# STM32U3C5 register map
File version: 1.0
CPU: CM33 r0p1, little endian, MPU, FPU, 4 interrupt priority bits
Registers are 32-bit, read-write, reset 0x0 unless marked. A register's access mark holds for its fields unless they carry their own. Offsets are from the block's base; [hi:lo] are bit positions; {n}, {i} and the like mark numbered series.

## SPI1 — SPI address block description
Base 0x40013000
Same registers: SPI3 0x40002000, SPI4 0x40002400, SPI2 0x40003800, SEC_SPI3 0x50002000, SEC_SPI4 0x50002400, SEC_SPI2 0x50003800, SEC_SPI1 0x50013000
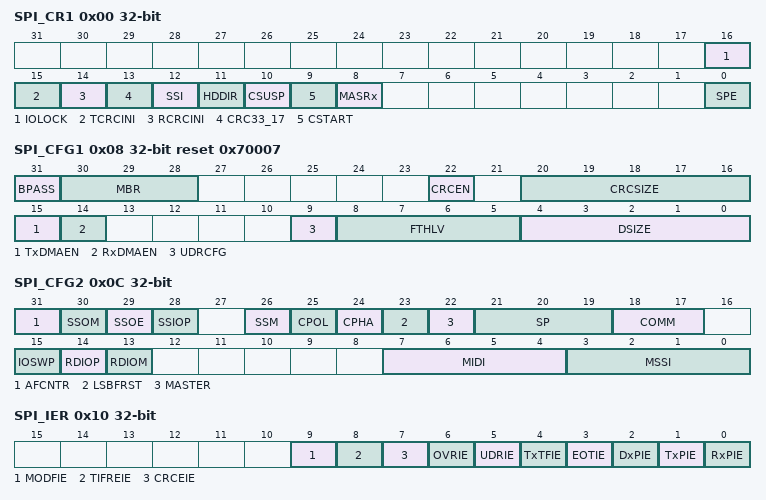
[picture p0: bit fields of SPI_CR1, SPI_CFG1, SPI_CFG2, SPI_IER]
0x00 SPI_CR1 — SPI control register 1
  [16] IOLOCK — locking the AF configuration of associated I/Os
    0=AF configuration is not locked; 1=AF configuration is locked
  [15] TCRCINI — CRC calculation initialization pattern control for transmitter
    0=all zero pattern is applied; 1=all ones pattern is applied
  [14] RCRCINI — CRC calculation initialization pattern control for receiver
    0=All zero pattern is applied; 1=All ones pattern is applied
  [13] CRC33_17 — Full size (33-bit or 17-bit) CRC polynomial configuration
    0=Full size (33-bit or 17-bit) CRC polynomial is not used; 1=Full size (33-bit or 17-bit) CRC polynomial is used
  [12] SSI — internal SS signal input level
  [11] HDDIR — Rx/Tx direction at half-duplex mode
    0=SPI is receiver; 1=SPI is transmitter
  [10] CSUSP wo — master suspend request
  [9] CSTART — master transfer start
    0=master transfer is at idle; 1=master transfer is ongoing or temporary suspended by automatic suspend
  [8] MASRx — master automatic suspension in Receive mode
    0=SPI flow/clock generation is continuous, regardless of overrun condition; 1=SPI flow is suspended temporary on RxFIFO full condition, before reaching overrun condition
  [0] SPE — serial peripheral enable
    0=Serial peripheral disabled; 1=Serial peripheral enabled
0x04 SPI_CR2 — SPI control register 2
  [15:0] TSIZE — number of data at current transfer
0x08 SPI_CFG1 reset 0x70007 — SPI configuration register 1
  [31] BPASS — bypass of the prescaler at master baud rate clock generator
    0=bypass is disabled; 1=bypass is enabled
  [30:28] MBR — master baud rate prescaler setting
    0=SPI master clock/2; 1=SPI master clock/4; 2=SPI master clock/8; 3=SPI master clock/16; 4=SPI master clock/32; 5=SPI master clock/64; 6=SPI master clock/128; 7=SPI master clock/256
  [22] CRCEN — hardware CRC computation enable
    0=CRC calculation disabled; 1=CRC calculation enabled
  [20:16] CRCSIZE — length of CRC frame to be transacted and compared
    {v}={v+1}-bits (v=3..7); 29=30-bits; 30=31-bits; 31=32-bits
  [15] TxDMAEN — Tx DMA stream enable
    0=Tx DMA disabled; 1=Tx DMA enabled
  [14] RxDMAEN — Rx DMA stream enable
    0=Rx-DMA disabled; 1=Rx-DMA enabled
  [9] UDRCFG — behavior of slave transmitter at underrun condition
    0=slave sends a constant pattern defined by the user at the SPI_UDRDR register; 1=Slave repeats lastly received data from master
  [8:5] FTHLV — FIFO threshold level
    {v}={v+1}-data (v=0..15)
  [4:0] DSIZE — number of bits in a single SPI data frame
    {v}={v+1} bits (v=3..7); 29=30 bits; 30=31 bits; 31=32 bits
0x0C SPI_CFG2 — SPI configuration register 2
  [31] AFCNTR — alternate function GPIOs control
    0=The peripheral takes no control of GPIOs while it is disabled; 1=The peripheral keeps always control of all associated GPIOs
  [30] SSOM — SS output management in master mode
    0=SS is kept at active level until data transfer is completed, it becomes inactive with EOT flag; 1=SPI data frames are interleaved with SS nonactive pulses when MIDI[3:0]>1
  [29] SSOE — SS output enable
    0=SS output is disabled and the SPI can work in multimaster configuration; 1=SS output is enabled
  [28] SSIOP — SS input/output polarity
    0=low level is active for SS signal; 1=high level is active for SS signal
  [26] SSM — software management of SS signal input
    0=SS input value is determined by the SS PAD; 1=SS input value is determined by the SSI bit
  [25] CPOL — clock polarity
    0=SCK signal is at 0 when idle; 1=SCK signal is at 1 when idle
  [24] CPHA — clock phase
    0=the first clock transition is the first data capture edge; 1=the second clock transition is the first data capture edge
  [23] LSBFRST — data frame format
    0=MSB transmitted first; 1=LSB transmitted first
  [22] MASTER — SPI master
    0=SPI slave; 1=SPI master
  [21:19] SP — serial protocol
    0=SPI Motorola; 1=SPI TI
  [18:17] COMM — SPI Communication Mode
    0=full-duplex; 1=simplex transmitter; 2=simplex receiver; 3=half-duplex
  [15] IOSWP — swap functionality of MISO and MOSI pins
    0=no swap; 1=MOSI and MISO are swapped
  [14] RDIOP — RDY signal input/output polarity
    0=high level of the signal means the slave is ready for communication; 1=low level of the signal means the slave is ready for communication
  [13] RDIOM — RDY signal input/output management
    0=RDY signal is defined internally fixed as permanently active (RDIOP setting has no effect); 1=RDY signal is overtaken from alternate function input (at master case) or output (at slave case) of the dedicated pin (RDIOP setting takes effect)
  [7:4] MIDI — master Inter-Data Idleness
    0=no delay; 1=1 clock cycle period delay; 15=15 clock cycle periods delay
  [3:0] MSSI — Master SS Idleness
    0=no extra delay; 1=1 clock cycle period delay added; 15=15 clock cycle periods delay added
0x10 SPI_IER — SPI interrupt enable register
  [9] MODFIE — mode Fault interrupt enable
    0=MODF interrupt disabled; 1=MODF interrupt enabled
  [8] TIFREIE — TIFRE interrupt enable
    0=TIFRE interrupt disabled; 1=TIFRE interrupt enabled
  [7] CRCEIE — CRC error interrupt enable
    0=CRC interrupt disabled; 1=CRC interrupt enabled
  [6] OVRIE — OVR interrupt enable
    0=OVR interrupt disabled; 1=OVR interrupt enabled
  [5] UDRIE — UDR interrupt enable
    0=UDR interrupt disabled; 1=UDR interrupt enabled
  [4] TxTFIE — TxTF interrupt enable
    0=TxTF interrupt disabled; 1=TxTF interrupt enabled
  [3] EOTIE — EOT, SUSP and TxC interrupt enable
    0=EOT/SUSP/TxC interrupt disabled; 1=EOT/SUSP/TxC interrupt enabled
  [2] DxPIE — DxP interrupt enabled
    0=DxP interrupt disabled; 1=DxP interrupt enabled
  [1] TxPIE — TxP interrupt enable
    0=TxP interrupt disabled; 1=TxP interrupt enabled
  [0] RxPIE — RxP interrupt enable
    0=RxP interrupt disabled; 1=RxP interrupt enabled
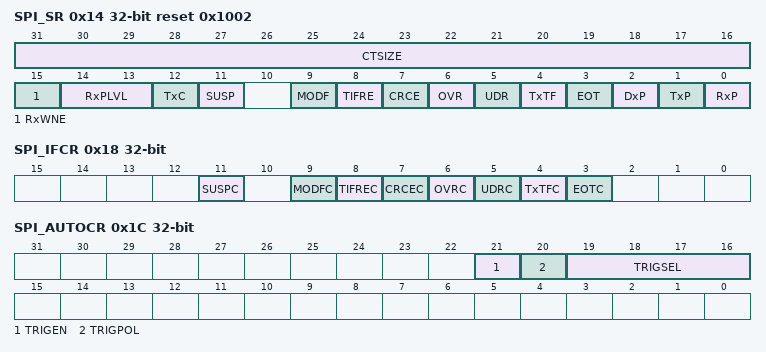
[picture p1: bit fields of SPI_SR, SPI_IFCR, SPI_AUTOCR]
0x14 SPI_SR ro reset 0x1002 — SPI status register
  [31:16] CTSIZE — number of data frames remaining in current TSIZE session
  [15] RxWNE — RxFIFO word not empty
    0=less than four bytes of RxFIFO space is occupied by data; 1=at least four bytes of RxFIFO space is occupied by data
  [14:13] RxPLVL — RxFIFO packing level
    0=no next frame is available at RxFIFO; 1=1 frame is available; 2=2 frames are availablex; 3=3 frames are availablex
  [12] TxC — TxFIFO transmission complete
    0=current data transaction is still ongoing, data is available in TxFIFO or last frame transmission is on going; 1=last TxFIFO frame transmission complete
  [11] SUSP — suspension status
    0=SPI not suspended (master mode active or other mode); 1=master mode is suspended (current frame completed)
  [9] MODF — mode fault
    0=no mode fault; 1=mode fault detected
  [8] TIFRE — TI frame format error
    0=no TI Frame Error; 1=TI frame error detected
  [7] CRCE — CRC error
    0=no CRC error; 1=CRC error detected
  [6] OVR — overrun
    0=no overrun; 1=overrun detected
  [5] UDR — underrun
    0=no underrun; 1=underrun detected
  [4] TxTF — transmission transfer filled
    0=upload of TxFIFO is ongoing or not started; 1=TxFIFO upload is finished
  [3] EOT — end of transfer
    0=transfer is ongoing or not started; 1=transfer complete
  [2] DxP — duplex packet
    0=TxFIFO is Full and/or RxFIFO is Empty; 1=both TxFIFO has space for write and RxFIFO contains for read a single packet at least
  [1] TxP — Tx-packet space available
    0=not enough free space at TxFIFO to host next data packet; 1=enough free space at TxFIFO to host at least one data packet
  [0] RxP — Rx-packet available
    0=RxFIFO is empty or an incomplete data packet is received; 1=RxFIFO contains at least one data packet
0x18 SPI_IFCR wo — SPI interrupt/status flags clear register
  [11] SUSPC — Suspend flag clear
  [9] MODFC — mode fault flag clear
  [8] TIFREC — TI frame format error flag clear
  [7] CRCEC — CRC error flag clear
  [6] OVRC — overrun flag clear
  [5] UDRC — underrun flag clear
  [4] TxTFC — transmission transfer filled flag clear
  [3] EOTC — end of transfer flag clear
0x1C SPI_AUTOCR — SPI autonomous mode control register
  [21] TRIGEN — Hardware control of CSTART triggering enable
    0=Hardware control disabled; 1=Hardware control enabled
  [20] TRIGPOL — Trigger polarity
    0=trigger is active on raising edge; 1=trigger is active on falling edge
  [19:16] TRIGSEL — Trigger selection (refer Section: Description of SPI interconnections).
    0=spi_trg0 is selected; 1=spi_trg1 is selected; 15=spi_trg15 is selected
0x20 SPI_TxDR wo — SPI transmit data register
  [31:0] TxDR — transmit data register
0x30 SPI_RxDR ro — SPI receive data register
  [31:0] RxDR — receive data register
0x40 SPI_CRCPOLY reset 0x107 — SPI polynomial register
  [31:0] CRCPOLY — CRC polynomial register
0x44 SPI_TxCRC ro — SPI transmitter CRC register
  [31:0] TxCRC — CRC register for transmitter
0x48 SPI_RxCRC ro — SPI receiver CRC register
  [31:0] RxCRC — CRC register for receiver
0x4C SPI_UDRDR — SPI underrun data register
  [31:0] UDRDR — data at slave underrun condition
